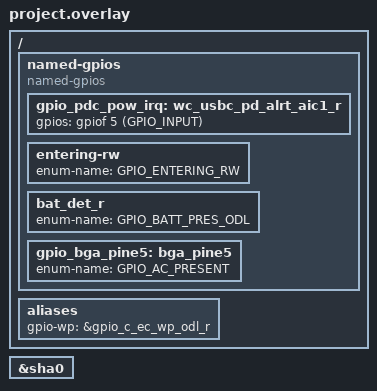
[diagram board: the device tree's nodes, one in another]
/* Copyright 2024 The ChromiumOS Authors
 * Use of this source code is governed by a BSD-style license that can be
 * found in the LICENSE file.
 */

/* fatcat program common DTS includes */

#include <cros/integrated_fwid.dtsi>

/* fatcat_it82002aw project DTS includes */

#include "generated.dtsi"

#define CHARGER_I2C i2c4

#define PD_POW_I2C i2c1
#define PD_POW_IRQ_GPIO &gpiof 5

/ {
	named-gpios {
		gpio_pdc_pow_irq: wc_usbc_pd_alrt_aic1_r {
			gpios = <&gpiof 5 (GPIO_INPUT)>;
		};
	};
};

#include "../../intelrvp/ptlrvp/battery.dtsi"
#include "../../intelrvp/ptlrvp/usbc.dtsi"
#include "../../intelrvp/ptlrvp/i2c.dtsi"
#include "../../intelrvp/ptlrvp/pd.dtsi"

#include "console.dtsi"
#include "adc.dtsi"
#include "keyboard.dtsi"
#include "i2c.dtsi"
#include "interrupts.dtsi"
#include "pwm.dtsi"

/* these need to be promoted to program.conf */

#include "binman.dtsi"

/* fatcat_it82002aw overrides follow... */

/ {
	aliases {
		 gpio-wp = &gpio_c_ec_wp_odl_r;

		 /*gpio_pdc_pow_irq = &gpio_wc_usbc_pd_alrt_aic1_r;*/
	};

	named-gpios {
		compatible = "named-gpios";

		/* The legacy system code requires GPIO_ENTERING_RW symbol */
		entering-rw {
			enum-name = "GPIO_ENTERING_RW";
		};
		bat_det_r {
			enum-name = "GPIO_BATT_PRES_ODL";
		};
		gpio_bga_pine5: bga_pine5 {
			enum-name = "GPIO_AC_PRESENT";
		};
	};
};

&sha0 {
	status = "okay";
};
